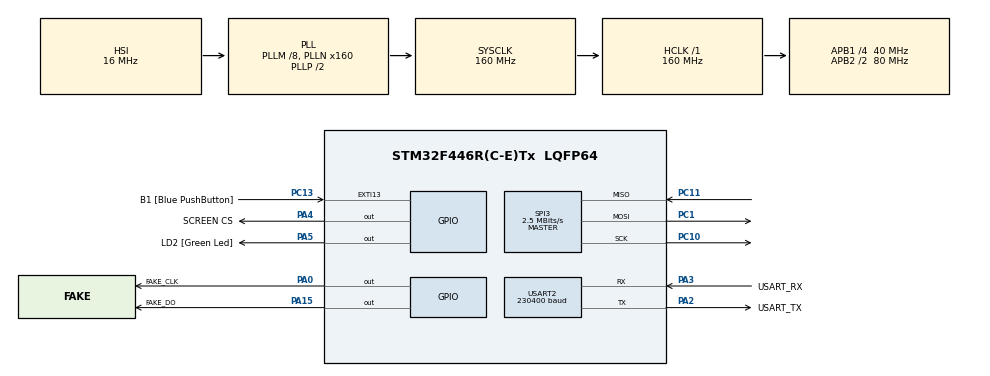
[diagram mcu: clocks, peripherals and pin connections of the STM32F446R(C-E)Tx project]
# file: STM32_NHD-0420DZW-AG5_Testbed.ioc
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Dma.Request0=SPI3_RX
Dma.Request1=SPI3_TX
Dma.Request2=USART2_RX
Dma.Request3=USART2_TX
Dma.SPI3_RX.0.Direction=DMA_PERIPH_TO_MEMORY
Dma.SPI3_RX.0.FIFOMode=DMA_FIFOMODE_DISABLE
Dma.SPI3_RX.0.Instance=DMA1_Stream0
Dma.SPI3_RX.0.MemDataAlignment=DMA_MDATAALIGN_BYTE
Dma.SPI3_RX.0.MemInc=DMA_MINC_ENABLE
Dma.SPI3_RX.0.Mode=DMA_NORMAL
Dma.SPI3_RX.0.PeriphDataAlignment=DMA_PDATAALIGN_BYTE
Dma.SPI3_RX.0.PeriphInc=DMA_PINC_DISABLE
Dma.SPI3_RX.0.Priority=DMA_PRIORITY_LOW
Dma.SPI3_TX.1.Direction=DMA_MEMORY_TO_PERIPH
Dma.SPI3_TX.1.FIFOMode=DMA_FIFOMODE_DISABLE
Dma.SPI3_TX.1.Instance=DMA1_Stream7
Dma.SPI3_TX.1.MemDataAlignment=DMA_MDATAALIGN_BYTE
Dma.SPI3_TX.1.MemInc=DMA_MINC_ENABLE
Dma.SPI3_TX.1.Mode=DMA_NORMAL
Dma.SPI3_TX.1.PeriphDataAlignment=DMA_PDATAALIGN_BYTE
Dma.SPI3_TX.1.PeriphInc=DMA_PINC_DISABLE
Dma.SPI3_TX.1.Priority=DMA_PRIORITY_MEDIUM
Dma.USART2_RX.2.Direction=DMA_PERIPH_TO_MEMORY
Dma.USART2_RX.2.FIFOMode=DMA_FIFOMODE_DISABLE
Dma.USART2_RX.2.Instance=DMA1_Stream5
Dma.USART2_RX.2.MemDataAlignment=DMA_MDATAALIGN_BYTE
Dma.USART2_RX.2.MemInc=DMA_MINC_ENABLE
Dma.USART2_RX.2.Mode=DMA_CIRCULAR
Dma.USART2_RX.2.PeriphDataAlignment=DMA_PDATAALIGN_BYTE
Dma.USART2_RX.2.PeriphInc=DMA_PINC_DISABLE
Dma.USART2_RX.2.Priority=DMA_PRIORITY_MEDIUM
Dma.USART2_TX.3.Direction=DMA_MEMORY_TO_PERIPH
Dma.USART2_TX.3.FIFOMode=DMA_FIFOMODE_DISABLE
Dma.USART2_TX.3.Instance=DMA1_Stream6
Dma.USART2_TX.3.MemDataAlignment=DMA_MDATAALIGN_BYTE
Dma.USART2_TX.3.MemInc=DMA_MINC_ENABLE
Dma.USART2_TX.3.Mode=DMA_NORMAL
Dma.USART2_TX.3.PeriphDataAlignment=DMA_PDATAALIGN_BYTE
Dma.USART2_TX.3.PeriphInc=DMA_PINC_DISABLE
Dma.USART2_TX.3.Priority=DMA_PRIORITY_LOW
FREERTOS.INCLUDE_eTaskGetState=1
FREERTOS.INCLUDE_vTaskDelayUntil=1
FREERTOS.INCLUDE_xQueueGetMutexHolder=1
FREERTOS.INCLUDE_xSemaphoreGetMutexHolder=1
FREERTOS.INCLUDE_xTaskGetCurrentTaskHandle=1
FREERTOS.Mutexes01=swMtx,Dynamic,NULL
FREERTOS.Queues01=mainCanTxQ,32,Can_frame_t,NULL,Dynamic,NULL,NULL;mainCanRxQ,32,Can_frame_t,NULL,Dynamic,NULL,NULL
FREERTOS.Tasks01=Application,0,512,doApplication,Default,NULL,Dynamic,NULL,NULL;Can_Processor,-1,512,doProcessCan,Default,NULL,Dynamic,NULL,NULL
FREERTOS.Timers01=WWDGTmr,TmrKickDog,osTimerPeriodic,Default,NULL,Dynamic,NULL;HBTmr,TmrSendHB,osTimerPeriodic,Default,NULL,Dynamic,NULL
FREERTOS.configCHECK_FOR_STACK_OVERFLOW=2
FREERTOS.configENABLE_BACKWARD_COMPATIBILITY=0
FREERTOS.configMINIMAL_STACK_SIZE=256
FREERTOS.configTIMER_TASK_PRIORITY=6
FREERTOS.configTOTAL_HEAP_SIZE=32768
FREERTOS.configUSE_MALLOC_FAILED_HOOK=1
FREERTOS.configUSE_PORT_OPTIMISED_TASK_SELECTION=1
FREERTOS.configUSE_TIMERS=1
FREERTOS.configUSE_TRACE_FACILITY=0
Mcu.Family=STM32F4
Mcu.Name=STM32F446R(C-E)Tx
Mcu.Package=LQFP64
NVIC.DMA1_Stream0_IRQn=true\:5\:0\:false\:false\:true\:true
NVIC.DMA1_Stream5_IRQn=true\:5\:0\:false\:false\:true\:true
NVIC.DMA1_Stream6_IRQn=true\:5\:0\:false\:false\:true\:true
NVIC.DMA1_Stream7_IRQn=true\:5\:0\:false\:false\:true\:true
NVIC.EXTI15_10_IRQn=true\:5\:0\:false\:false\:true\:true
NVIC.PriorityGroup=NVIC_PRIORITYGROUP_4
NVIC.TIM6_DAC_IRQn=true\:0\:0\:false\:false\:true\:false
NVIC.TimeBase=TIM6_DAC_IRQn
NVIC.TimeBaseIP=TIM6
NVIC.USART2_IRQn=true\:5\:0\:false\:false\:true\:true
PA0-WKUP.GPIO_Label=FAKE_CLK
PA0-WKUP.GPIO_ModeDefaultOutputPP=GPIO_MODE_OUTPUT_OD
PA0-WKUP.GPIO_Speed=GPIO_SPEED_FREQ_VERY_HIGH
PA0-WKUP.PinState=GPIO_PIN_SET
PA0-WKUP.Signal=GPIO_Output
PA1.GPIO_Label=BRK_ADC
PA1.Signal=ADCx_IN1
PA13.GPIO_Label=TMS
PA13.Mode=Serial_Wire
PA13.Signal=SYS_JTMS-SWDIO
PA14.GPIO_Label=TCK
PA14.Mode=Serial_Wire
PA14.Signal=SYS_JTCK-SWCLK
PA15.GPIO_Label=FAKE_DO
PA15.GPIO_ModeDefaultOutputPP=GPIO_MODE_OUTPUT_OD
PA15.GPIO_Speed=GPIO_SPEED_FREQ_VERY_HIGH
PA15.PinState=GPIO_PIN_SET
PA15.Signal=GPIO_Output
PA2.GPIO_Label=USART_TX
PA2.Mode=Asynchronous
PA2.Signal=USART2_TX
PA3.GPIO_Label=USART_RX
PA3.Mode=Asynchronous
PA3.Signal=USART2_RX
PA4.GPIO_Label=SCREEN CS
PA4.GPIO_Speed=GPIO_SPEED_FREQ_VERY_HIGH
PA4.PinState=GPIO_PIN_SET
PA4.Signal=GPIO_Output
PA5.GPIO_Label=LD2 [Green Led]
PA5.Signal=GPIO_Output
PB3.GPIO_Label=SWO
PB3.Signal=SYS_JTDO-SWO
PC1.GPIO_PuPd=GPIO_PULLUP
PC1.Mode=Full_Duplex_Master
PC1.Signal=SPI3_MOSI
PC10.GPIO_PuPd=GPIO_PULLUP
PC10.Mode=Full_Duplex_Master
PC10.Signal=SPI3_SCK
PC11.GPIO_PuPd=GPIO_PULLUP
PC11.Mode=Full_Duplex_Master
PC11.Signal=SPI3_MISO
PC13.GPIO_Label=B1 [Blue PushButton]
PC13.GPIO_ModeDefaultEXTI=GPIO_MODE_IT_FALLING
PC13.Signal=GPXTI13
PC14-OSC32_IN.Mode=LSE-External-Oscillator
PC14-OSC32_IN.Signal=RCC_OSC32_IN
PC15-OSC32_OUT.Mode=LSE-External-Oscillator
PC15-OSC32_OUT.Signal=RCC_OSC32_OUT
PH0-OSC_IN.Signal=RCC_OSC_IN
PH1-OSC_OUT.Signal=RCC_OSC_OUT
ProjectManager.HeapSize=0x200
ProjectManager.StackSize=0x400
ProjectManager.TargetToolchain=EWARM
RCC.AHBFreq_Value=160000000
RCC.APB1CLKDivider=RCC_HCLK_DIV4
RCC.APB1Freq_Value=40000000
RCC.APB1TimFreq_Value=80000000
RCC.APB2CLKDivider=RCC_HCLK_DIV2
RCC.APB2Freq_Value=80000000
RCC.APB2TimFreq_Value=160000000
RCC.CortexFreq_Value=160000000
RCC.FLatency-AdvancedSettings=FLASH_LATENCY_5
RCC.HCLKFreq_Value=160000000
RCC.HSE_VALUE=8000000
RCC.HSI_VALUE=16000000
RCC.PLLM=8
RCC.PLLN=160
RCC.PLLQ=7
RCC.RCC_PERIPHCLK_CK48Var=RCC_PERIPHCLK_CLK48
RCC.RCC_PERIPHCLK_SDIOVar=RCC_PERIPHCLK_SDIO
RCC.RCC_PERIPHCLK_SPDIFVar=RCC_PERIPHCLK_SPDIFRX
RCC.RCC_RTC_Clock_SourceVirtual=RCC_RTCCLKSOURCE_LSE
RCC.SYSCLKFreq_VALUE=160000000
RCC.SYSCLKSource=RCC_SYSCLKSOURCE_PLLCLK
RCC.USBFreq_Value=45714285.71428572
RCC.VCOOutputFreq_Value=320000000
SH.ADCx_IN1.0=ADC1_IN1
SPI3.BaudRatePrescaler=SPI_BAUDRATEPRESCALER_16
SPI3.CLKPhase=SPI_PHASE_2EDGE
SPI3.CLKPolarity=SPI_POLARITY_HIGH
SPI3.CalculateBaudRate=2.5 MBits/s
SPI3.Direction=SPI_DIRECTION_2LINES
SPI3.Mode=SPI_MODE_MASTER
SPI3.VirtualType=VM_MASTER
USART2.BaudRate=230400
USART2.VirtualMode=VM_ASYNC
VP_FREERTOS_VS_ENABLE.Mode=Enabled
VP_SYS_VS_tim6.Mode=TIM6
VP_WWDG_VS_WWDG.Mode=WWDG_Activate
WWDG.Counter=127
WWDG.Prescaler=WWDG_PRESCALER_8
WWDG.Window=127
board=NUCLEO-F446RE

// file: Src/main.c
/**
  ******************************************************************************
  * File Name          : main.c
  * Description        : Main program body
  ******************************************************************************
  *
  * Copyright (c) 2017 STMicroelectronics International N.V.
  * All rights reserved.
  *
  * Redistribution and use in source and binary forms, with or without
  * modification, are permitted, provided that the following conditions are met:
  *
  * 1. Redistribution of source code must retain the above copyright notice,
  *    this list of conditions and the following disclaimer.
  * 2. Redistributions in binary form must reproduce the above copyright notice,
  *    this list of conditions and the following disclaimer in the documentation
  *    and/or other materials provided with the distribution.
  * 3. Neither the name of STMicroelectronics nor the names of other
  *    contributors to this software may be used to endorse or promote products
  *    derived from this software without specific written permission.
  * 4. This software, including modifications and/or derivative works of this
  *    software, must execute solely and exclusively on microcontroller or
  *    microprocessor devices manufactured by or for STMicroelectronics.
  * 5. Redistribution and use of this software other than as permitted under
  *    this license is void and will automatically terminate your rights under
  *    this license.
  *
  * THIS SOFTWARE IS PROVIDED BY STMICROELECTRONICS AND CONTRIBUTORS "AS IS"
  * AND ANY EXPRESS, IMPLIED OR STATUTORY WARRANTIES, INCLUDING, BUT NOT
  * LIMITED TO, THE IMPLIED WARRANTIES OF MERCHANTABILITY, FITNESS FOR A
  * PARTICULAR PURPOSE AND NON-INFRINGEMENT OF THIRD PARTY INTELLECTUAL PROPERTY
  * RIGHTS ARE DISCLAIMED TO THE FULLEST EXTENT PERMITTED BY LAW. IN NO EVENT
  * SHALL STMICROELECTRONICS OR CONTRIBUTORS BE LIABLE FOR ANY DIRECT, INDIRECT,
  * INCIDENTAL, SPECIAL, EXEMPLARY, OR CONSEQUENTIAL DAMAGES (INCLUDING, BUT NOT
  * LIMITED TO, PROCUREMENT OF SUBSTITUTE GOODS OR SERVICES; LOSS OF USE, DATA,
  * OR PROFITS; OR BUSINESS INTERRUPTION) HOWEVER CAUSED AND ON ANY THEORY OF
  * LIABILITY, WHETHER IN CONTRACT, STRICT LIABILITY, OR TORT (INCLUDING
  * NEGLIGENCE OR OTHERWISE) ARISING IN ANY WAY OUT OF THE USE OF THIS SOFTWARE,
  * EVEN IF ADVISED OF THE POSSIBILITY OF SUCH DAMAGE.
  *
  ******************************************************************************
  */
#include "main.h"
#include "stm32f4xx_hal.h"
#include "cmsis_os.h"

SPI_HandleTypeDef hspi3;
DMA_HandleTypeDef hdma_spi3_rx;
DMA_HandleTypeDef hdma_spi3_tx;

UART_HandleTypeDef huart2;
DMA_HandleTypeDef hdma_usart2_rx;
DMA_HandleTypeDef hdma_usart2_tx;

WWDG_HandleTypeDef hwwdg;

osThreadId ApplicationHandle;
osThreadId Can_ProcessorHandle;
osMessageQId mainCanTxQHandle;
osMessageQId mainCanRxQHandle;
osTimerId WWDGTmrHandle;
osTimerId HBTmrHandle;
osMutexId swMtxHandle;

/* USER CODE BEGIN PV */
/* Private variables ---------------------------------------------------------*/

/* USER CODE END PV */

void SystemClock_Config(void);
void Error_Handler(void);
static void MX_GPIO_Init(void);
static void MX_DMA_Init(void);
static void MX_USART2_UART_Init(void);
static void MX_WWDG_Init(void);
static void MX_SPI3_Init(void);
void doApplication(void const * argument);
void doProcessCan(void const * argument);
void TmrKickDog(void const * argument);
void TmrSendHB(void const * argument);

/* USER CODE BEGIN PFP */
/* Private function prototypes -----------------------------------------------*/

/* USER CODE END PFP */

int main(void)
{

  /* MCU Configuration----------------------------------------------------------*/

  /* Reset of all peripherals, Initializes the Flash interface and the Systick. */
  HAL_Init();

  /* Configure the system clock */
  SystemClock_Config();

  /* Initialize all configured peripherals */
  MX_GPIO_Init();
  MX_DMA_Init();
  MX_USART2_UART_Init();
  MX_WWDG_Init();
  MX_SPI3_Init();

  /* USER CODE BEGIN 2 */
  Oled_begin(&hspi3);
  Oled_writeCatDataSync(12,"Hello world!");

  /* USER CODE END 2 */

  /* Create the mutex(es) */
  /* definition and creation of swMtx */
  osMutexDef(swMtx);
  swMtxHandle = osMutexCreate(osMutex(swMtx));

  /* Create the timer(s) */
  /* definition and creation of WWDGTmr */
  osTimerDef(WWDGTmr, TmrKickDog);
  WWDGTmrHandle = osTimerCreate(osTimer(WWDGTmr), osTimerPeriodic, NULL);

  /* definition and creation of HBTmr */
  osTimerDef(HBTmr, TmrSendHB);
  HBTmrHandle = osTimerCreate(osTimer(HBTmr), osTimerPeriodic, NULL);

  /* Create the thread(s) */
  /* definition and creation of Application */
  osThreadDef(Application, doApplication, osPriorityNormal, 0, 512);
  ApplicationHandle = osThreadCreate(osThread(Application), NULL);

  /* definition and creation of Can_Processor */
  osThreadDef(Can_Processor, doProcessCan, osPriorityBelowNormal, 0, 512);
  Can_ProcessorHandle = osThreadCreate(osThread(Can_Processor), NULL);

  /* Create the queue(s) */
  /* definition and creation of mainCanTxQ */
  osMessageQDef(mainCanTxQ, 32, Can_frame_t);
  mainCanTxQHandle = osMessageCreate(osMessageQ(mainCanTxQ), NULL);

  /* definition and creation of mainCanRxQ */
  osMessageQDef(mainCanRxQ, 32, Can_frame_t);
  mainCanRxQHandle = osMessageCreate(osMessageQ(mainCanRxQ), NULL);

  /* Start scheduler */
  osKernelStart();

  /* We should never get here as control is now taken by the scheduler */

  /* Infinite loop */
  while (1)
  {

  }

}

/** System Clock Configuration
*/
void SystemClock_Config(void)
{

  RCC_OscInitTypeDef RCC_OscInitStruct;
  RCC_ClkInitTypeDef RCC_ClkInitStruct;

    /**Configure the main internal regulator output voltage
    */
  __HAL_RCC_PWR_CLK_ENABLE();

  __HAL_PWR_VOLTAGESCALING_CONFIG(PWR_REGULATOR_VOLTAGE_SCALE1);

    /**Initializes the CPU, AHB and APB busses clocks
    */
  RCC_OscInitStruct.OscillatorType = RCC_OSCILLATORTYPE_HSI;
  RCC_OscInitStruct.HSIState = RCC_HSI_ON;
  RCC_OscInitStruct.HSICalibrationValue = 16;
  RCC_OscInitStruct.PLL.PLLState = RCC_PLL_ON;
  RCC_OscInitStruct.PLL.PLLSource = RCC_PLLSOURCE_HSI;
  RCC_OscInitStruct.PLL.PLLM = 8;
  RCC_OscInitStruct.PLL.PLLN = 160;
  RCC_OscInitStruct.PLL.PLLP = RCC_PLLP_DIV2;
  RCC_OscInitStruct.PLL.PLLQ = 7;
  RCC_OscInitStruct.PLL.PLLR = 2;
  if (HAL_RCC_OscConfig(&RCC_OscInitStruct) != HAL_OK)
  {
    Error_Handler();
  }

    /**Initializes the CPU, AHB and APB busses clocks
    */
  RCC_ClkInitStruct.ClockType = RCC_CLOCKTYPE_HCLK|RCC_CLOCKTYPE_SYSCLK
                              |RCC_CLOCKTYPE_PCLK1|RCC_CLOCKTYPE_PCLK2;
  RCC_ClkInitStruct.SYSCLKSource = RCC_SYSCLKSOURCE_PLLCLK;
  RCC_ClkInitStruct.AHBCLKDivider = RCC_SYSCLK_DIV1;
  RCC_ClkInitStruct.APB1CLKDivider = RCC_HCLK_DIV4;
  RCC_ClkInitStruct.APB2CLKDivider = RCC_HCLK_DIV2;

  if (HAL_RCC_ClockConfig(&RCC_ClkInitStruct, FLASH_LATENCY_5) != HAL_OK)
  {
    Error_Handler();
  }

    /**Configure the Systick interrupt time
    */
  HAL_SYSTICK_Config(HAL_RCC_GetHCLKFreq()/1000);

    /**Configure the Systick
    */
  HAL_SYSTICK_CLKSourceConfig(SYSTICK_CLKSOURCE_HCLK);

  /* SysTick_IRQn interrupt configuration */
  HAL_NVIC_SetPriority(SysTick_IRQn, 15, 0);
}

/* SPI3 init function */
static void MX_SPI3_Init(void)
{

  hspi3.Instance = SPI3;
  hspi3.Init.Mode = SPI_MODE_MASTER;
  hspi3.Init.Direction = SPI_DIRECTION_2LINES;
  hspi3.Init.DataSize = SPI_DATASIZE_8BIT;
  hspi3.Init.CLKPolarity = SPI_POLARITY_HIGH;
  hspi3.Init.CLKPhase = SPI_PHASE_2EDGE;
  hspi3.Init.NSS = SPI_NSS_SOFT;
  hspi3.Init.BaudRatePrescaler = SPI_BAUDRATEPRESCALER_16;
  hspi3.Init.FirstBit = SPI_FIRSTBIT_MSB;
  hspi3.Init.TIMode = SPI_TIMODE_DISABLE;
  hspi3.Init.CRCCalculation = SPI_CRCCALCULATION_DISABLE;
  hspi3.Init.CRCPolynomial = 10;
  if (HAL_SPI_Init(&hspi3) != HAL_OK)
  {
    Error_Handler();
  }

}

/* USART2 init function */
static void MX_USART2_UART_Init(void)
{

  huart2.Instance = USART2;
  huart2.Init.BaudRate = 230400;
  huart2.Init.WordLength = UART_WORDLENGTH_8B;
  huart2.Init.StopBits = UART_STOPBITS_1;
  huart2.Init.Parity = UART_PARITY_NONE;
  huart2.Init.Mode = UART_MODE_TX_RX;
  huart2.Init.HwFlowCtl = UART_HWCONTROL_NONE;
  huart2.Init.OverSampling = UART_OVERSAMPLING_16;
  if (HAL_UART_Init(&huart2) != HAL_OK)
  {
    Error_Handler();
  }

}

/* WWDG init function */
static void MX_WWDG_Init(void)
{

  hwwdg.Instance = WWDG;
  hwwdg.Init.Prescaler = WWDG_PRESCALER_8;
  hwwdg.Init.Window = 127;
  hwwdg.Init.Counter = 127;
  hwwdg.Init.EWIMode = WWDG_EWI_DISABLE;
  if (HAL_WWDG_Init(&hwwdg) != HAL_OK)
  {
    Error_Handler();
  }

}

static void MX_DMA_Init(void)
{
  /* DMA controller clock enable */
  __HAL_RCC_DMA1_CLK_ENABLE();

  /* DMA interrupt init */
  /* DMA1_Stream0_IRQn interrupt configuration */
  HAL_NVIC_SetPriority(DMA1_Stream0_IRQn, 5, 0);
  HAL_NVIC_EnableIRQ(DMA1_Stream0_IRQn);
  /* DMA1_Stream5_IRQn interrupt configuration */
  HAL_NVIC_SetPriority(DMA1_Stream5_IRQn, 5, 0);
  HAL_NVIC_EnableIRQ(DMA1_Stream5_IRQn);
  /* DMA1_Stream6_IRQn interrupt configuration */
  HAL_NVIC_SetPriority(DMA1_Stream6_IRQn, 5, 0);
  HAL_NVIC_EnableIRQ(DMA1_Stream6_IRQn);
  /* DMA1_Stream7_IRQn interrupt configuration */
  HAL_NVIC_SetPriority(DMA1_Stream7_IRQn, 5, 0);
  HAL_NVIC_EnableIRQ(DMA1_Stream7_IRQn);

}

/** Configure pins as
        * Analog
        * Input
        * Output
        * EVENT_OUT
        * EXTI
        * Free pins are configured automatically as Analog (this feature is enabled through
        * the Code Generation settings)
     PA1   ------> ADCx_IN1
*/
static void MX_GPIO_Init(void)
{

  GPIO_InitTypeDef GPIO_InitStruct;

  /* GPIO Ports Clock Enable */
  __HAL_RCC_GPIOC_CLK_ENABLE();
  __HAL_RCC_GPIOH_CLK_ENABLE();
  __HAL_RCC_GPIOA_CLK_ENABLE();
  __HAL_RCC_GPIOB_CLK_ENABLE();
  __HAL_RCC_GPIOD_CLK_ENABLE();

  /*Configure GPIO pin Output Level */
  HAL_GPIO_WritePin(GPIOA, FAKE_CLK_Pin|SCREEN_CS_Pin|FAKE_DO_Pin, GPIO_PIN_SET);

  /*Configure GPIO pin Output Level */
  HAL_GPIO_WritePin(LD2_GPIO_Port, LD2_Pin, GPIO_PIN_RESET);

  /*Configure GPIO pin : B1_Pin */
  GPIO_InitStruct.Pin = B1_Pin;
  GPIO_InitStruct.Mode = GPIO_MODE_IT_FALLING;
  GPIO_InitStruct.Pull = GPIO_NOPULL;
  HAL_GPIO_Init(B1_GPIO_Port, &GPIO_InitStruct);

  /*Configure GPIO pins : PC0 PC2 PC3 PC4
                           PC5 PC6 PC7 PC8
                           PC9 PC12 */
  GPIO_InitStruct.Pin = GPIO_PIN_0|GPIO_PIN_2|GPIO_PIN_3|GPIO_PIN_4
                          |GPIO_PIN_5|GPIO_PIN_6|GPIO_PIN_7|GPIO_PIN_8
                          |GPIO_PIN_9|GPIO_PIN_12;
  GPIO_InitStruct.Mode = GPIO_MODE_ANALOG;
  GPIO_InitStruct.Pull = GPIO_NOPULL;
  HAL_GPIO_Init(GPIOC, &GPIO_InitStruct);

  /*Configure GPIO pins : FAKE_CLK_Pin FAKE_DO_Pin */
  GPIO_InitStruct.Pin = FAKE_CLK_Pin|FAKE_DO_Pin;
  GPIO_InitStruct.Mode = GPIO_MODE_OUTPUT_OD;
  GPIO_InitStruct.Pull = GPIO_NOPULL;
  GPIO_InitStruct.Speed = GPIO_SPEED_FREQ_VERY_HIGH;
  HAL_GPIO_Init(GPIOA, &GPIO_InitStruct);

  /*Configure GPIO pins : BRK_ADC_Pin PA6 PA7 PA8
                           PA9 PA10 PA11 PA12 */
  GPIO_InitStruct.Pin = BRK_ADC_Pin|GPIO_PIN_6|GPIO_PIN_7|GPIO_PIN_8
                          |GPIO_PIN_9|GPIO_PIN_10|GPIO_PIN_11|GPIO_PIN_12;
  GPIO_InitStruct.Mode = GPIO_MODE_ANALOG;
  GPIO_InitStruct.Pull = GPIO_NOPULL;
  HAL_GPIO_Init(GPIOA, &GPIO_InitStruct);

  /*Configure GPIO pin : SCREEN_CS_Pin */
  GPIO_InitStruct.Pin = SCREEN_CS_Pin;
  GPIO_InitStruct.Mode = GPIO_MODE_OUTPUT_PP;
  GPIO_InitStruct.Pull = GPIO_NOPULL;
  GPIO_InitStruct.Speed = GPIO_SPEED_FREQ_VERY_HIGH;
  HAL_GPIO_Init(SCREEN_CS_GPIO_Port, &GPIO_InitStruct);

  /*Configure GPIO pin : LD2_Pin */
  GPIO_InitStruct.Pin = LD2_Pin;
  GPIO_InitStruct.Mode = GPIO_MODE_OUTPUT_PP;
  GPIO_InitStruct.Pull = GPIO_NOPULL;
  GPIO_InitStruct.Speed = GPIO_SPEED_FREQ_LOW;
  HAL_GPIO_Init(LD2_GPIO_Port, &GPIO_InitStruct);

  /*Configure GPIO pins : PB0 PB1 PB2 PB10
                           PB12 PB13 PB14 PB15
                           PB4 PB5 PB6 PB7
                           PB8 PB9 */
  GPIO_InitStruct.Pin = GPIO_PIN_0|GPIO_PIN_1|GPIO_PIN_2|GPIO_PIN_10
                          |GPIO_PIN_12|GPIO_PIN_13|GPIO_PIN_14|GPIO_PIN_15
                          |GPIO_PIN_4|GPIO_PIN_5|GPIO_PIN_6|GPIO_PIN_7
                          |GPIO_PIN_8|GPIO_PIN_9;
  GPIO_InitStruct.Mode = GPIO_MODE_ANALOG;
  GPIO_InitStruct.Pull = GPIO_NOPULL;
  HAL_GPIO_Init(GPIOB, &GPIO_InitStruct);

  /*Configure GPIO pin : PD2 */
  GPIO_InitStruct.Pin = GPIO_PIN_2;
  GPIO_InitStruct.Mode = GPIO_MODE_ANALOG;
  GPIO_InitStruct.Pull = GPIO_NOPULL;
  HAL_GPIO_Init(GPIOD, &GPIO_InitStruct);

  /* EXTI interrupt init*/
  HAL_NVIC_SetPriority(EXTI15_10_IRQn, 5, 0);
  HAL_NVIC_EnableIRQ(EXTI15_10_IRQn);

}

/* doApplication function */
void doApplication(void const * argument)
{

  /* USER CODE BEGIN 5 */
  /* Infinite loop */
  for(;;)
  {
	  Oled_writeOneData('F');
    osDelay(1000);
  }
  /* USER CODE END 5 */
}

/* doProcessCan function */
void doProcessCan(void const * argument)
{
  for(;;)
  {
    osDelay(1);
  }
}

/* TmrKickDog function */
void TmrKickDog(void const * argument)
{
}

/* TmrSendHB function */
void TmrSendHB(void const * argument)
{
}

void HAL_TIM_PeriodElapsedCallback(TIM_HandleTypeDef *htim)
{
  if (htim->Instance == TIM6) {
    HAL_IncTick();
  }
}

void Error_Handler(void)
{
  while(1)
  {
  }
}

/************************ (C) COPYRIGHT STMicroelectronics *****END OF FILE****/
